# EFR32MG24A010F1536IM40 register map
Vendor: Silicon Labs; Series: EFR32; File version: B
Registers are 32-bit, read-write, reset 0x0 unless marked. A register's access mark holds for its fields unless they carry their own. Offsets are from the block's base; [hi:lo] are bit positions; 'fields as' and 'values as' point back to an identical list.

## WDOG0_S — WDOG0_S Registers
Base 0x4B004000
Same registers: WDOG1_S 0x4B008000, WDOG0_NS 0x5B004000, WDOG1_NS 0x5B008000
0x00 IPVERSION ro reset 0x1
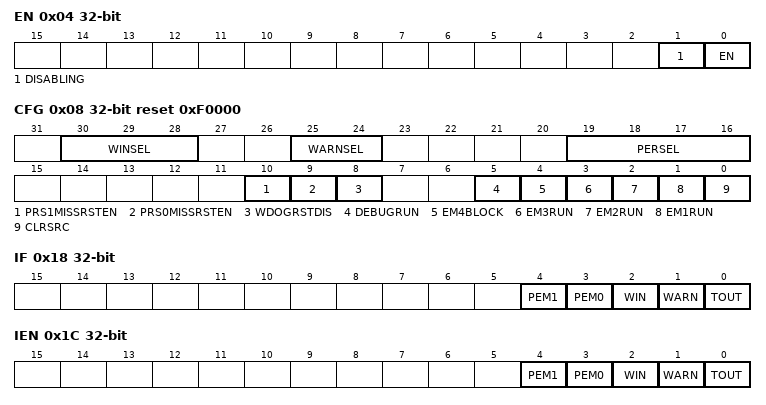
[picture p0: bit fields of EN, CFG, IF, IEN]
0x04 EN
  [1] DISABLING ro — Disabling busy status
  [0] EN — Module Enable
0x08 CFG reset 0xF0000
  [30:28] WINSEL — WDOG Illegal Window Select
    0=DIS (Disabled.); 1=SEL1 (Window timeout is 12.5% of the Timeout.); 2=SEL2 (Window timeout is 25% of the Timeout.); 3=SEL3 (Window timeout is 37.5% of the Timeout.); 4=SEL4 (Window timeout is 50% of the Timeout.); 5=SEL5 (Window timeout is 62.5% of the Timeout.); 6=SEL6 (Window timeout is 75.5% of the Timeout.); 7=SEL7 (Window timeout is 87.5% of the Timeout.)
  [25:24] WARNSEL — WDOG Warning Period Select
    0=DIS (Disable); 1=SEL1 (Warning timeout is 25% of the Timeout.); 2=SEL2 (Warning timeout is 50% of the Timeout.); 3=SEL3 (Warning timeout is 75% of the Timeout.)
  [19:16] PERSEL — WDOG Timeout Period Select
    0=SEL0 (Timeout period of 9 wdog cycles); 1=SEL1 (Timeout period of 17 wdog cycles); 2=SEL2 (Timeout period of 33 wdog cycles); 3=SEL3 (Timeout period of 65 wdog cycles); 4=SEL4 (Timeout period of 129 wdog cycles); 5=SEL5 (Timeout period of 257 wdog cycles); 6=SEL6 (Timeout period of 513 wdog cycles); 7=SEL7 (Timeout period of 1k wdog cycles); 8=SEL8 (Timeout period of 2k wdog cycles); 9=SEL9 (Timeout period of 4k wdog cycles); 10=SEL10 (Timeout period of 8k wdog cycles); 11=SEL11 (Timeout period of 16k wdog cycles); 12=SEL12 (Timeout period of 32k wdog cycles); 13=SEL13 (Timeout period of 64k wdog cycles); 14=SEL14 (Timeout period of 128k wdog cycles); 15=SEL15 (Timeout period of 256k wdog cycles)
  [10] PRS1MISSRSTEN — PRS Src1 Missing Event WDOG Reset
  [9] PRS0MISSRSTEN — PRS Src0 Missing Event WDOG Reset
  [8] WDOGRSTDIS — WDOG Reset Disable
    0=EN (A timeout will cause a WDOG reset); 1=DIS (A timeout will not cause a WDOG reset)
  [5] DEBUGRUN — Debug Mode Run
    0=DISABLE (WDOG timer is frozen in debug mode); 1=ENABLE (WDOG timer is running in debug mode)
  [4] EM4BLOCK
    0=DISABLE (EM4 can be entered by software. See EMU for detailed description.); 1=ENABLE (EM4 cannot be entered by software.)
  [3] EM3RUN
    0=DISABLE (WDOG timer is frozen in EM3.); 1=ENABLE (WDOG timer is running in EM3.)
  [2] EM2RUN
    0=DISABLE (WDOG timer is frozen in EM2.); 1=ENABLE (WDOG timer is running in EM2.)
  [1] EM1RUN
    values as EM2RUN
  [0] CLRSRC — WDOG Clear Source
    0=SW (A write to the clear bit will clear the WDOG counter); 1=PRSSRC0 (A rising edge on the PRS Source 0 will clear the WDOG counter)
0x0C CMD wo
  [0] CLEAR — WDOG Timer Clear
    0=UNCHANGED (WDOG timer is unchanged.); 1=CLEARED (WDOG timer is cleared to 0.)
0x14 STATUS ro
  [31] LOCK — WDOG Configuration Lock Status
    0=UNLOCKED (All WDOG lockable registers are unlocked.); 1=LOCKED (All WDOG lockable registers are locked.)
0x18 IF
  [4] PEM1 — PRS Src1 Event Missing Interrupt Flag
  [3] PEM0 — PRS Src0 Event Missing Interrupt Flag
  [2] WIN — WDOG Window Interrupt Flag
  [1] WARN — WDOG Warning Timeout Interrupt Flag
  [0] TOUT — WDOG Timeout Interrupt Flag
0x1C IEN
  [4] PEM1 — PRS Src1 Event Missing Interrupt Enable
  [3] PEM0 — PRS Src0 Event Missing Interrupt Enable
  [2] WIN — WDOG Window Interrupt Enable
  [1] WARN — WDOG Warning Timeout Interrupt Enable
  [0] TOUT — WDOG Timeout Interrupt Enable
0x20 LOCK wo reset 0xABE8
  [15:0] LOCKKEY — WDOG Configuration Lock
    0=LOCK (Lock WDOG lockable registers); 0xABE8=UNLOCK (Unlock WDOG lockable registers)
0x24 SYNCBUSY ro
  [0] CMD — Sync Busy for Cmd Register

## SEMAILBOX_S_HOST — SEMAILBOX_S_HOST Registers
Base 0x4C000000
Same registers: SEMAILBOX_NS_HOST 0x5C000000
0x00 FIFO — A write access to any address in this area will be mapped to the TX FIFO (only for the payload). A read access to any address in this area will be mapped to the RX FIFO (only for the payload). Using an address range (16 x 32-bit) rather than one single address mapped to the FIFO allows using incremental bursts.
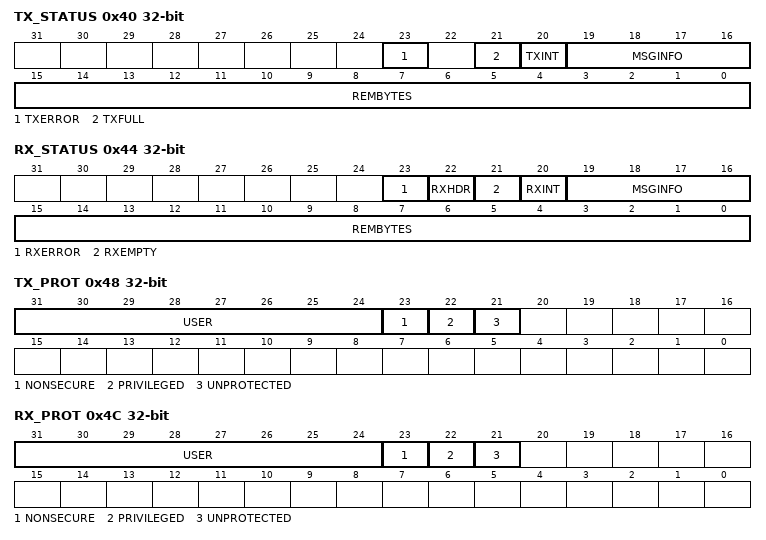
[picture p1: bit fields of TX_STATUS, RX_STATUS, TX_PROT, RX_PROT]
0x40 TX_STATUS ro
  [23] TXERROR, [21] TXFULL, [20] TXINT, [19:16] MSGINFO, [15:0] REMBYTES
0x44 RX_STATUS ro
  [23] RXERROR, [22] RXHDR, [21] RXEMPTY, [20] RXINT, [19:16] MSGINFO, [15:0] REMBYTES
0x48 TX_PROT ro — TX Protection register.
  [31:24] USER, [23] NONSECURE, [22] PRIVILEGED, [21] UNPROTECTED
0x4C RX_PROT ro — RX Protection register.
  [31:24] USER, [23] NONSECURE, [22] PRIVILEGED, [21] UNPROTECTED
0x50 TX_HEADER wo — A write access to this register will be mapped to the TX FIFO (only for header).
  [31:0] TXHEADER
0x54 RX_HEADER ro — A read access to this register will be mapped to the RX FIFO (only for the header).
  [31:0] RXHEADER
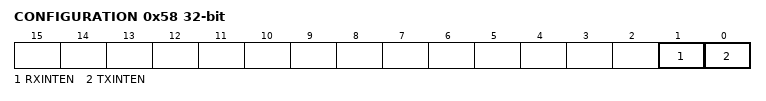
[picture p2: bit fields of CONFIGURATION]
0x58 CONFIGURATION
  [1] RXINTEN, [0] TXINTEN
